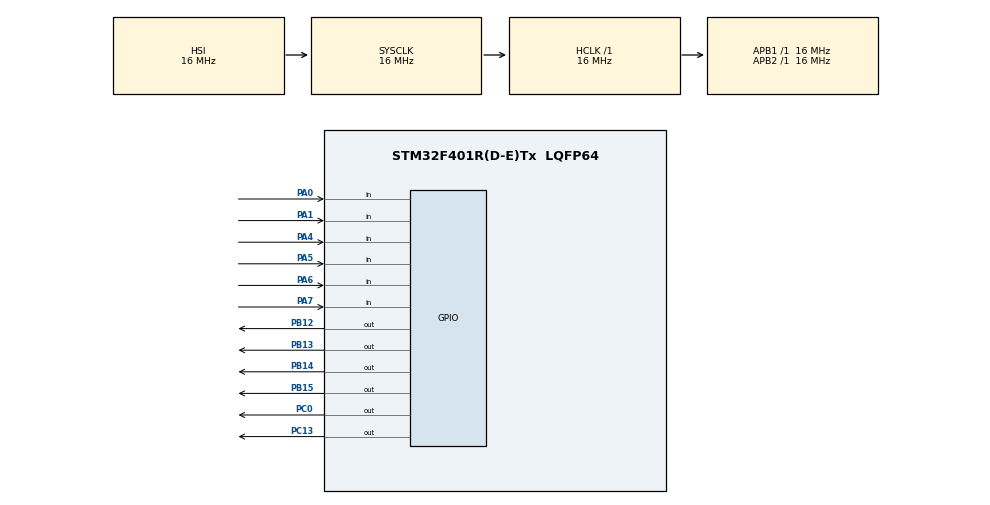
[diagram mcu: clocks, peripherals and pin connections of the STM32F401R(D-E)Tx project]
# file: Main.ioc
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Mcu.Family=STM32F4
Mcu.Name=STM32F401R(D-E)Tx
Mcu.Package=LQFP64
NVIC.PriorityGroup=NVIC_PRIORITYGROUP_4
PA0-WKUP.GPIO_PuPd=GPIO_PULLUP
PA0-WKUP.Signal=GPIO_Input
PA1.GPIO_PuPd=GPIO_PULLDOWN
PA1.Signal=GPIO_Input
PA13.Mode=JTAG_4_pins
PA13.Signal=SYS_JTMS-SWDIO
PA14.Mode=JTAG_4_pins
PA14.Signal=SYS_JTCK-SWCLK
PA15.Mode=JTAG_4_pins
PA15.Signal=SYS_JTDI
PA4.Signal=GPIO_Input
PA5.Signal=GPIO_Input
PA6.Signal=GPIO_Input
PA7.Signal=GPIO_Input
PB12.Signal=GPIO_Output
PB13.Signal=GPIO_Output
PB14.Signal=GPIO_Output
PB15.Signal=GPIO_Output
PB3.Mode=JTAG_4_pins
PB3.Signal=SYS_JTDO-SWO
PC0.Signal=GPIO_Output
PC13-ANTI_TAMP.PinState=GPIO_PIN_SET
PC13-ANTI_TAMP.Signal=GPIO_Output
ProjectManager.HeapSize=0x200
ProjectManager.StackSize=0x400
ProjectManager.TargetToolchain=MDK-ARM V5.32
RCC.AHBFreq_Value=16000000
RCC.APB1Freq_Value=16000000
RCC.APB2Freq_Value=16000000
RCC.CortexFreq_Value=16000000
RCC.HSE_VALUE=25000000
RCC.HSI_VALUE=16000000
RCC.LSE_VALUE=32768
RCC.SYSCLKFreq_VALUE=16000000
RCC.VCOOutputFreq_Value=192000000
board=custom

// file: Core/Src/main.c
/* USER CODE BEGIN Header */
/**
  ******************************************************************************
  * @file           : main.c
  * @brief          : Main program body
  ******************************************************************************
  * @attention
  *
  * Copyright (c) 2026 STMicroelectronics.
  * All rights reserved.
  *
  * This software is licensed under terms that can be found in the LICENSE file
  * in the root directory of this software component.
  * If no LICENSE file comes with this software, it is provided AS-IS.
  *
  ******************************************************************************
  */
/* USER CODE END Header */
#include "main.h"

void SystemClock_Config(void);
static void MX_GPIO_Init(void);

int main(void)
{

  /* MCU Configuration--------------------------------------------------------*/

  /* Reset of all peripherals, Initializes the Flash interface and the Systick. */
  HAL_Init();

  /* Configure the system clock */
  SystemClock_Config();

  /* Initialize all configured peripherals */
  MX_GPIO_Init();

  /* Infinite loop */
	while (1){

    /* USER CODE BEGIN 3 */
		if (HAL_GPIO_ReadPin(GPIOA, GPIO_PIN_0) == GPIO_PIN_RESET){
				HAL_GPIO_WritePin(GPIOC, GPIO_PIN_13, GPIO_PIN_RESET);
		}

		if (HAL_GPIO_ReadPin(GPIOA, GPIO_PIN_1) == GPIO_PIN_SET){
			HAL_GPIO_WritePin(GPIOC, GPIO_PIN_13, GPIO_PIN_SET);
		}

		uint32_t value = (GPIOA->IDR >> 4UL) & 0x0FUL;

		uint32_t temp = GPIOB->ODR;
		temp = (temp & ~(0x0FUL << 12UL)) | (value << 12UL);
		GPIOB->ODR = temp;
  }
  /* USER CODE END 3 */
}

void SystemClock_Config(void)
{
  RCC_OscInitTypeDef RCC_OscInitStruct = {0};
  RCC_ClkInitTypeDef RCC_ClkInitStruct = {0};

  /** Configure the main internal regulator output voltage
  */
  __HAL_RCC_PWR_CLK_ENABLE();
  __HAL_PWR_VOLTAGESCALING_CONFIG(PWR_REGULATOR_VOLTAGE_SCALE2);

  /** Initializes the RCC Oscillators according to the specified parameters
  * in the RCC_OscInitTypeDef structure.
  */
  RCC_OscInitStruct.OscillatorType = RCC_OSCILLATORTYPE_HSI;
  RCC_OscInitStruct.HSIState = RCC_HSI_ON;
  RCC_OscInitStruct.HSICalibrationValue = RCC_HSICALIBRATION_DEFAULT;
  RCC_OscInitStruct.PLL.PLLState = RCC_PLL_NONE;
  if (HAL_RCC_OscConfig(&RCC_OscInitStruct) != HAL_OK)
  {
    Error_Handler();
  }

  /** Initializes the CPU, AHB and APB buses clocks
  */
  RCC_ClkInitStruct.ClockType = RCC_CLOCKTYPE_HCLK|RCC_CLOCKTYPE_SYSCLK
                              |RCC_CLOCKTYPE_PCLK1|RCC_CLOCKTYPE_PCLK2;
  RCC_ClkInitStruct.SYSCLKSource = RCC_SYSCLKSOURCE_HSI;
  RCC_ClkInitStruct.AHBCLKDivider = RCC_SYSCLK_DIV1;
  RCC_ClkInitStruct.APB1CLKDivider = RCC_HCLK_DIV1;
  RCC_ClkInitStruct.APB2CLKDivider = RCC_HCLK_DIV1;

  if (HAL_RCC_ClockConfig(&RCC_ClkInitStruct, FLASH_LATENCY_0) != HAL_OK)
  {
    Error_Handler();
  }
}

static void MX_GPIO_Init(void)
{
  GPIO_InitTypeDef GPIO_InitStruct = {0};

  /* GPIO Ports Clock Enable */
  __HAL_RCC_GPIOC_CLK_ENABLE();
  __HAL_RCC_GPIOA_CLK_ENABLE();
  __HAL_RCC_GPIOB_CLK_ENABLE();

  /*Configure GPIO pin Output Level */
  HAL_GPIO_WritePin(GPIOC, GPIO_PIN_13, GPIO_PIN_SET);

  /*Configure GPIO pin Output Level */
  HAL_GPIO_WritePin(GPIOC, GPIO_PIN_0, GPIO_PIN_RESET);

  /*Configure GPIO pin Output Level */
  HAL_GPIO_WritePin(GPIOB, GPIO_PIN_12|GPIO_PIN_13|GPIO_PIN_14|GPIO_PIN_15, GPIO_PIN_RESET);

  /*Configure GPIO pins : PC13 PC0 */
  GPIO_InitStruct.Pin = GPIO_PIN_13|GPIO_PIN_0;
  GPIO_InitStruct.Mode = GPIO_MODE_OUTPUT_PP;
  GPIO_InitStruct.Pull = GPIO_NOPULL;
  GPIO_InitStruct.Speed = GPIO_SPEED_FREQ_LOW;
  HAL_GPIO_Init(GPIOC, &GPIO_InitStruct);

  /*Configure GPIO pin : PA0 */
  GPIO_InitStruct.Pin = GPIO_PIN_0;
  GPIO_InitStruct.Mode = GPIO_MODE_INPUT;
  GPIO_InitStruct.Pull = GPIO_PULLUP;
  HAL_GPIO_Init(GPIOA, &GPIO_InitStruct);

  /*Configure GPIO pin : PA1 */
  GPIO_InitStruct.Pin = GPIO_PIN_1;
  GPIO_InitStruct.Mode = GPIO_MODE_INPUT;
  GPIO_InitStruct.Pull = GPIO_PULLDOWN;
  HAL_GPIO_Init(GPIOA, &GPIO_InitStruct);

  /*Configure GPIO pins : PA4 PA5 PA6 PA7 */
  GPIO_InitStruct.Pin = GPIO_PIN_4|GPIO_PIN_5|GPIO_PIN_6|GPIO_PIN_7;
  GPIO_InitStruct.Mode = GPIO_MODE_INPUT;
  GPIO_InitStruct.Pull = GPIO_NOPULL;
  HAL_GPIO_Init(GPIOA, &GPIO_InitStruct);

  /*Configure GPIO pins : PB12 PB13 PB14 PB15 */
  GPIO_InitStruct.Pin = GPIO_PIN_12|GPIO_PIN_13|GPIO_PIN_14|GPIO_PIN_15;
  GPIO_InitStruct.Mode = GPIO_MODE_OUTPUT_PP;
  GPIO_InitStruct.Pull = GPIO_NOPULL;
  GPIO_InitStruct.Speed = GPIO_SPEED_FREQ_LOW;
  HAL_GPIO_Init(GPIOB, &GPIO_InitStruct);

}

void Error_Handler(void)
{
  __disable_irq();
  while (1)
  {
  }
}
